VERSION ""

NS_ :

BS_:

BU_: GATEWAY IVI

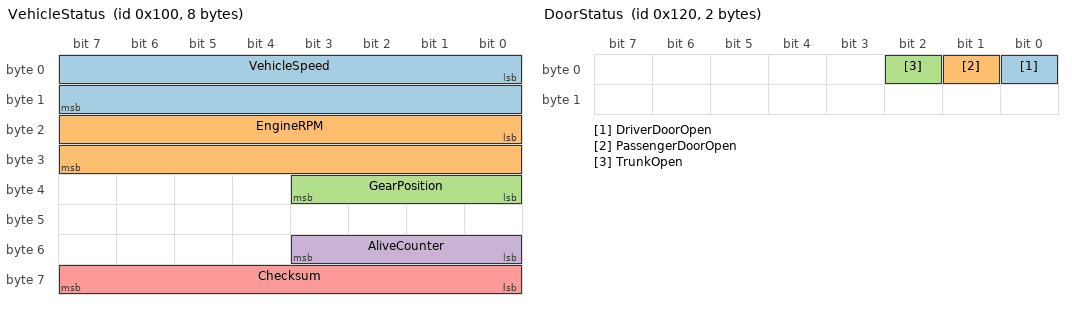
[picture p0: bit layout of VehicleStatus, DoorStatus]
BO_ 256 VehicleStatus: 8 GATEWAY
 SG_ VehicleSpeed : 0|16@1+ (0.1,0) [0|255] "km/h" IVI
 SG_ EngineRPM : 16|16@1+ (0.25,0) [0|8000] "rpm" IVI
 SG_ GearPosition : 32|4@1+ (1,0) [0|8] "" IVI
 SG_ AliveCounter : 48|4@1+ (1,0) [0|15] "" IVI
 SG_ Checksum : 56|8@1+ (1,0) [0|255] "" IVI

BO_ 288 DoorStatus: 2 GATEWAY
 SG_ DriverDoorOpen : 0|1@1+ (1,0) [0|1] "" IVI
 SG_ PassengerDoorOpen : 1|1@1+ (1,0) [0|1] "" IVI
 SG_ TrunkOpen : 2|1@1+ (1,0) [0|1] "" IVI

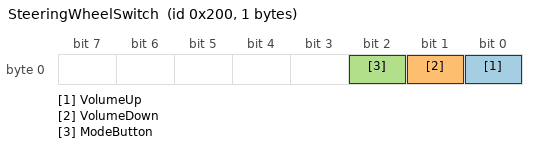
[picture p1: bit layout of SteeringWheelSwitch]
BO_ 512 SteeringWheelSwitch: 1 GATEWAY
 SG_ VolumeUp : 0|1@1+ (1,0) [0|1] "" IVI
 SG_ VolumeDown : 1|1@1+ (1,0) [0|1] "" IVI
 SG_ ModeButton : 2|1@1+ (1,0) [0|1] "" IVI

CM_ BO_ 256 "차량 상태 정보. 주기 100ms";
CM_ BO_ 288 "도어 개폐 상태. 주기 200ms";
CM_ BO_ 512 "스티어링 휠 리모컨. 이벤트 전송";
